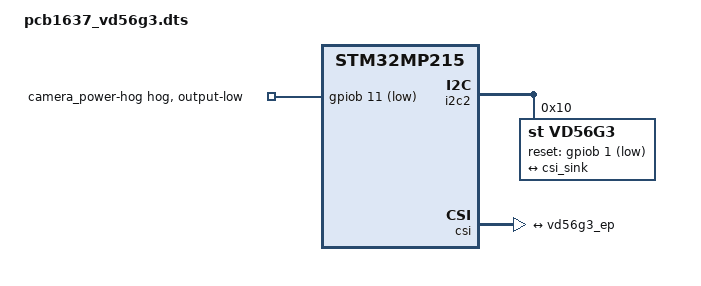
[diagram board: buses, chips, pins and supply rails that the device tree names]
/dts-v1/;
/plugin/;

/{
	compatible = "st,stm32mp215-dk";

        /include/ "disable_imx335.dtsi"

	fragment@0 {
		target = <&i2c2>;
		__overlay__ {
			#address-cells = <1>;
			#size-cells = <0>;
			vd56g3: camera@10 {
				compatible = "st,vd56g3";
				reg = <0x10>;

				clocks = <&clk_ext_camera>;
				clock-names = "xclk";

				reset-gpios = <&gpiob 1 1>; /* GPIO_ACTIVE_LOW | GPIO_PUSH_PULL */
				orientation = <0>;
				rotation = <2>;

				st,leds = <6>;

				port {
					vd56g3_ep: endpoint {
						clock-lanes = <0>;
						data-lanes = <1 2>;
						remote-endpoint = <&csi_sink>;
						clock-noncontinuous;
						link-frequencies =
							/bits/ 64 <402000000>;
					};
				};
			};
		};
	};

	fragment@1 {
		target = <&csi>;
		__overlay__ {
			ports {
				port@0 {
					csi_sink: endpoint {
						remote-endpoint = <&vd56g3_ep>;
					};
				};
			};
		};
	};

	fragment@2 {
		target = <&gpiob>;
		__overlay__ {
			camera_power-hog {
				gpio-hog;
				gpios = <11 1>;
				output-low;
			};
		};
	};
};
